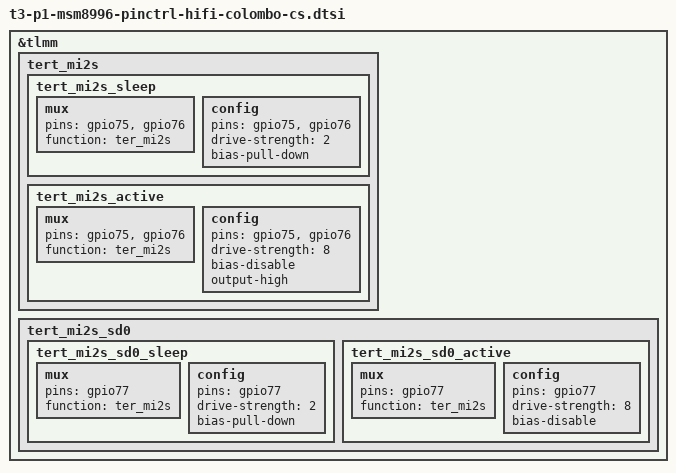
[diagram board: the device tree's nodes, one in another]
/* It inherits from t3-p1-msm8996-pinctrl-surabaya.dtsi */

&tlmm{
	tert_mi2s {
		tert_mi2s_sleep: tert_mi2s_sleep {
			mux {
				pins = "gpio75", "gpio76";
				function = "ter_mi2s";
			};

			config {
				pins = "gpio75", "gpio76";
				drive-strength = <2>;   /* 2 mA */
				bias-pull-down;         /* PULL DOWN */
			};
		};
		tert_mi2s_active: tert_mi2s_active {
			mux {
				pins = "gpio75", "gpio76";
				function = "ter_mi2s";
			};

			config {
				pins = "gpio75", "gpio76";
				drive-strength = <8>;   /* 8 mA */
				bias-disable;           /* NO PULL */
				output-high;
			};
		};
	};

//	tert_mi2s_mclk {
//		tert_mi2s_mclk_sleep: tert_mi2s_mclk_sleep {
//			mux {
//				pins = "gpio74";
//				function = "gpio";
//			};
//
//			config {
//				pins = "gpio74";
//				drive-strength = <2>;   /* 2 mA */
//				bias-disable;
//			};
//		};
//		tert_mi2s_mclk_active: tert_mi2s_mclk_active {
//			mux {
//				pins = "gpio74";
//				function = "gpio";
//			};
//
//			config {
//				pins = "gpio74";
//				drive-strength = <2>;   /* 2 mA */
//				bias-disable;
//			};
//		};
//	};

	tert_mi2s_sd0 {
		tert_mi2s_sd0_sleep: tert_mi2s_sd0_sleep {
			mux {
				pins = "gpio77";
				function = "ter_mi2s";
			};

			config {
				pins = "gpio77";
				drive-strength = <2>;   /* 2 mA */
				bias-pull-down;         /* PULL DOWN */
			};
		};
		tert_mi2s_sd0_active: tert_mi2s_sd0_active {
			mux {
				pins = "gpio77";
				function = "ter_mi2s";
			};

			config {
				pins = "gpio77";
				drive-strength = <8>;   /* 8 mA */
				bias-disable;           /* NO PULL */
			};
		};
	};
};
